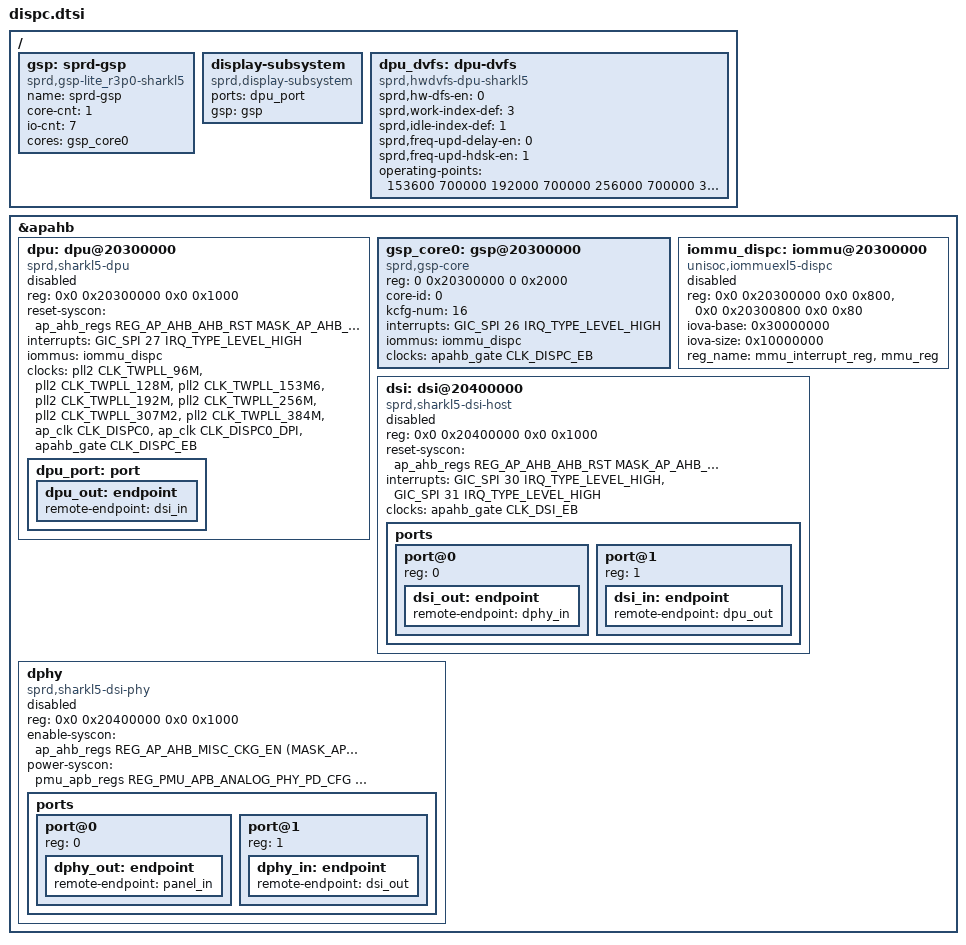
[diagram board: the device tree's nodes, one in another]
// SPDX-License-Identifier: GPL-2.0-only
/*
 * Unisoc UMS512 Clock DTS file
 *
 * Copyright (C) 2022, Unisoc Inc.
 */

&apahb {
	dpu: dpu@20300000 {
		compatible = "sprd,sharkl5-dpu";
		reg = <0x0 0x20300000 0x0 0x1000>;
		reset-syscon = <&ap_ahb_regs REG_AP_AHB_AHB_RST
				MASK_AP_AHB_DISPC_SOFT_RST>;
		interrupts = <GIC_SPI 27 IRQ_TYPE_LEVEL_HIGH>;
		status = "disabled";
		iommus = <&iommu_dispc>;
		//sprd,qos = <&dpu_qos>;

		dpu_port: port {
			dpu_out: endpoint {
				remote-endpoint = <&dsi_in>;
			};
		};
	};

	gsp_core0: gsp@20300000 {
		compatible = "sprd,gsp-core";
		reg = <0 0x20300000  0 0x2000>;
		core-id = <0>;
		kcfg-num = <16>;
		interrupts = <GIC_SPI 26 IRQ_TYPE_LEVEL_HIGH>;
		iommus = <&iommu_dispc>;
	};

	iommu_dispc: iommu@20300000 {
		compatible = "unisoc,iommuexl5-dispc";
		reg = <0x0 0x20300000 0x0 0x800>,
		      <0x0 0x20300800 0x0 0x80>;
		iova-base = <0x30000000>;
		iova-size = <0x10000000>;
		reg_name = "mmu_interrupt_reg","mmu_reg";
		status = "disabled";
		#iommu-cells = <0>;
	};

	dsi: dsi@20400000 {
		compatible = "sprd,sharkl5-dsi-host";
		reg = <0x0 0x20400000 0x0 0x1000>;
		reset-syscon = <&ap_ahb_regs REG_AP_AHB_AHB_RST
			MASK_AP_AHB_DSI_SOFT_RST>;
		interrupts = <GIC_SPI 30 IRQ_TYPE_LEVEL_HIGH>,
			<GIC_SPI 31 IRQ_TYPE_LEVEL_HIGH>;
		status = "disabled";

		ports {
			#address-cells = <1>;
			#size-cells = <0>;

			port@0 {
				reg = <0>;
				dsi_out: endpoint {
					remote-endpoint = <&dphy_in>;
				};
			};

			port@1 {
				reg = <1>;
				dsi_in: endpoint {
					remote-endpoint = <&dpu_out>;
				};
			};
		};
	};

	dphy: dphy {
		compatible = "sprd,sharkl5-dsi-phy";
		#address-cells = <1>;
		#size-cells = <0>;
		reg = <0x0 0x20400000 0x0 0x1000>;
		enable-syscon = <&ap_ahb_regs REG_AP_AHB_MISC_CKG_EN
				(MASK_AP_AHB_DPHY_REF_CKG_EN |
				MASK_AP_AHB_DPHY_CFG_CKG_EN)>;
		power-syscon = <&pmu_apb_regs REG_PMU_APB_ANALOG_PHY_PD_CFG
				MASK_PMU_APB_DSI_PD_REG>;
		status = "disabled";

		ports {
			#address-cells = <1>;
			#size-cells = <0>;

			port@0 {
				reg = <0>;
				dphy_out: endpoint {
					remote-endpoint = <&panel_in>;
				};
			};

			port@1 {
				reg = <1>;
				dphy_in: endpoint {
					remote-endpoint = <&dsi_out>;
				};
			};
		};
	};
};

&dpu {
	clock-names = "clk_src_96m",
			"clk_src_128m",
			"clk_src_153m6",
			"clk_src_192m",
			"clk_src_256m",
			"clk_src_307m2",
			"clk_src_384m",
			"clk_dpu_core",
			"clk_dpu_dpi",
			"clk_ap_ahb_disp_eb";

	clocks = <&pll2 CLK_TWPLL_96M>,
		<&pll2 CLK_TWPLL_128M>,
		<&pll2 CLK_TWPLL_153M6>,
		<&pll2 CLK_TWPLL_192M>,
		<&pll2 CLK_TWPLL_256M>,
		<&pll2 CLK_TWPLL_307M2>,
		<&pll2 CLK_TWPLL_384M>,
		<&ap_clk CLK_DISPC0>,
		<&ap_clk CLK_DISPC0_DPI>,
		<&apahb_gate CLK_DISPC_EB>;
};

&gsp_core0 {
	clock-names = "clk_ap_ahb_disp_eb";

	clocks = <&apahb_gate CLK_DISPC_EB>;
};

&dsi {
	clock-names = "clk_ap_ahb_dsi_eb";
	clocks = <&apahb_gate CLK_DSI_EB>;
};

/ {
	gsp: sprd-gsp {
	compatible = "sprd,gsp-lite_r3p0-sharkl5";
	name = "sprd-gsp";
	core-cnt = <1>;
	io-cnt = <7>;
	cores = <&gsp_core0>;
	};

	display-subsystem {
			compatible = "sprd,display-subsystem";
			ports = <&dpu_port>;
			gsp = <&gsp>;
	};

	dpu_dvfs: dpu-dvfs {
		compatible = "sprd,hwdvfs-dpu-sharkl5";
		sprd,hw-dfs-en = <0>;
		sprd,work-index-def = <3>;
		sprd,idle-index-def = <1>;
		sprd,freq-upd-delay-en = <0>;
		sprd,freq-upd-hdsk-en = <1>;

		operating-points = <
			/* kHz    uV */
			153600    700000
			192000    700000
			256000    700000
			307200    700000
			384000    750000
			>;
	};
};
